# MK20D5 register map
Vendor: Freescale Semiconductor, Inc.; Series: Kinetis_K; File version: 1.6
CPU: CM4 r0p1, little endian, no MPU, no FPU, VTOR, 4 interrupt priority bits
Registers are 32-bit, read-write, reset 0x0 unless marked. A register's access mark holds for its fields unless they carry their own. Offsets are from the block's base; [hi:lo] are bit positions; {n}, {i} and the like mark numbered series.

## USB0 — Universal Serial Bus, OTG Capable Controller
Base 0x40072000; register names take the prefix USB0_
0x00 PERID 8-bit ro reset 0x4 — Peripheral ID Register
  [5:0] ID — Peripheral identification bits
0x04 IDCOMP 8-bit ro reset 0xFB — Peripheral ID Complement Register
  [5:0] NID — Ones complement of peripheral identification bits.
0x08 REV 8-bit ro reset 0x33 — Peripheral Revision Register
  [7:0] REV — Revision
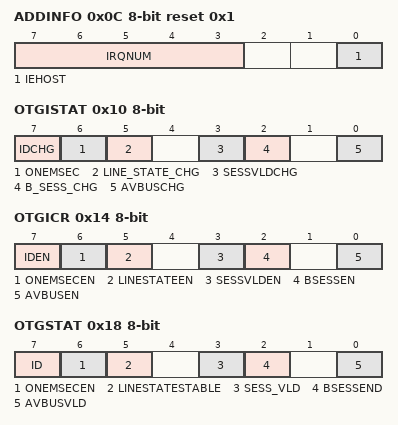
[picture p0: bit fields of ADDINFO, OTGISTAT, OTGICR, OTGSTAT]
0x0C ADDINFO 8-bit ro reset 0x1 — Peripheral Additional Info Register
  [7:3] IRQNUM — Assigned Interrupt Request Number
  [0] IEHOST — This bit is set if host mode is enabled.
0x10 OTGISTAT 8-bit — OTG Interrupt Status Register
  [7] IDCHG — This bit is set when a change in the ID Signal from the USB connector is sensed.
  [6] ONEMSEC — This bit is set when the 1 millisecond timer expires
  [5] LINE_STATE_CHG — This bit is set when the USB line state changes
  [3] SESSVLDCHG — This bit is set when a change in VBUS is detected indicating a session valid or a session no longer valid
  [2] B_SESS_CHG — This bit is set when a change in VBUS is detected on a B device.
  [0] AVBUSCHG — This bit is set when a change in VBUS is detected on an A device.
0x14 OTGICR 8-bit — OTG Interrupt Control Register
  [7] IDEN — ID interrupt enable
    0=The ID interrupt is disabled; 1=The ID interrupt is enabled
  [6] ONEMSECEN — 1 millisecond interrupt enable
    0=The 1msec timer interrupt is disabled; 1=The 1msec timer interrupt is enabled
  [5] LINESTATEEN — Line State change interrupt enable
    0=The LINE_STAT_CHG interrupt is disabled; 1=The LINE_STAT_CHG interrupt is enabled
  [3] SESSVLDEN — Session valid interrupt enable
    0=The SESSVLDCHG interrupt is disabled; 1=The SESSVLDCHG interrupt is enabled
  [2] BSESSEN — B Session END interrupt enable
    0=The B_SESS_CHG interrupt is disabled; 1=The B_SESS_CHG interrupt is enabled
  [0] AVBUSEN — A VBUS Valid interrupt enable
    0=The AVBUSCHG interrupt is disabled; 1=The AVBUSCHG interrupt is enabled
0x18 OTGSTAT 8-bit — OTG Status Register
  [7] ID — Indicates the current state of the ID pin on the USB connector
    0=Indicates a Type A cable has been plugged into the USB connector; 1=Indicates no cable is attached or a Type B cable has been plugged into the USB connector
  [6] ONEMSECEN — This bit is reserved for the 1msec count, but it is not useful to software.
  [5] LINESTATESTABLE — This bit indicates that the internal signals that control the LINE_STATE_CHG bit (bit 5) of the OTGISTAT register have been stable for at least 1 millisecond
    0=The LINE_STAT_CHG bit is not yet stable; 1=The LINE_STAT_CHG bit has been debounced and is stable
  [3] SESS_VLD — Session valid
    0=The VBUS voltage is below the B session Valid threshold; 1=The VBUS voltage is above the B session Valid threshold
  [2] BSESSEND — B Session END
    0=The VBUS voltage is above the B session End threshold; 1=The VBUS voltage is below the B session End threshold
  [0] AVBUSVLD — A VBUS Valid
    0=The VBUS voltage is below the A VBUS Valid threshold; 1=The VBUS voltage is above the A VBUS Valid threshold
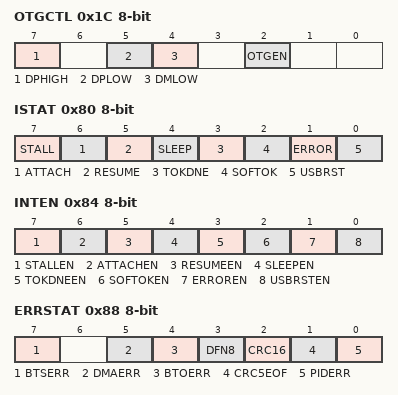
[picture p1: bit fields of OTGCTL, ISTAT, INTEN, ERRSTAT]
0x1C OTGCTL 8-bit — OTG Control Register
  [7] DPHIGH — D+ Data Line pullup resistor enable
    0=D+ pullup resistor is not enabled; 1=D+ pullup resistor is enabled
  [5] DPLOW — D+ Data Line pull-down resistor enable
    0=D+ pulldown resistor is not enabled; 1=D+ pulldown resistor is enabled
  [4] DMLOW — D- Data Line pull-down resistor enable
    0=D- pulldown resistor is not enabled; 1=D- pulldown resistor is enabled
  [2] OTGEN — On-The-Go pullup/pulldown resistor enable
    0=If USB_EN is set and HOST_MODE is clear in the Control Register (CTL), then the D+ Data Line pull-up resistors are enabled. If HOST_MODE is set the D+ and D- Data Line pull-down resistors are engaged.; 1=The pull-up and pull-down controls in this register are used
0x80 ISTAT 8-bit — Interrupt Status Register
  [7] STALL — Stall Interrupt
  [6] ATTACH — Attach Interrupt
  [5] RESUME — This bit is set depending upon the DP/DM signals, and can be used to signal remote wake-up signaling on the USB bus
  [4] SLEEP — This bit is set when the USB Module detects a constant idle on the USB bus for 3 milliseconds
  [3] TOKDNE — This bit is set when the current token being processed has completed
  [2] SOFTOK — This bit is set when the USB Module receives a Start Of Frame (SOF) token
  [1] ERROR — This bit is set when any of the error conditions within the ERRSTAT register occur
  [0] USBRST — This bit is set when the USB Module has decoded a valid USB reset
0x84 INTEN 8-bit — Interrupt Enable Register
  [7] STALLEN — STALL Interrupt Enable
    0=The STALL interrupt is not enabled; 1=The STALL interrupt is enabled
  [6] ATTACHEN — ATTACH Interrupt Enable
    0=The ATTACH interrupt is not enabled; 1=The ATTACH interrupt is enabled
  [5] RESUMEEN — RESUME Interrupt Enable
    0=The RESUME interrupt is not enabled; 1=The RESUME interrupt is enabled
  [4] SLEEPEN — SLEEP Interrupt Enable
    0=The SLEEP interrupt is not enabled; 1=The SLEEP interrupt is enabled
  [3] TOKDNEEN — TOKDNE Interrupt Enable
    0=The TOKDNE interrupt is not enabled; 1=The TOKDNE interrupt is enabled
  [2] SOFTOKEN — SOFTOK Interrupt Enable
    0=The SOFTOK interrupt is not enabled; 1=The SOFTOK interrupt is enabled
  [1] ERROREN — ERROR Interrupt Enable
    0=The ERROR interrupt is not enabled; 1=The ERROR interrupt is enabled
  [0] USBRSTEN — USBRST Interrupt Enable
    0=The USBRST interrupt is not enabled; 1=The USBRST interrupt is enabled
0x88 ERRSTAT 8-bit — Error Interrupt Status Register
  [7] BTSERR — This bit is set when a bit stuff error is detected
  [5] DMAERR — This bit is set if the USB Module has requested a DMA access to read a new BDT but has not been given the bus before it needs to receive or transmit data
  [4] BTOERR — This bit is set when a bus turnaround timeout error occurs
  [3] DFN8 — This bit is set if the data field received was not 8 bits in length
  [2] CRC16 — This bit is set when a data packet is rejected due to a CRC16 error.
  [1] CRC5EOF — This error interrupt has two functions
  [0] PIDERR — This bit is set when the PID check field fails.
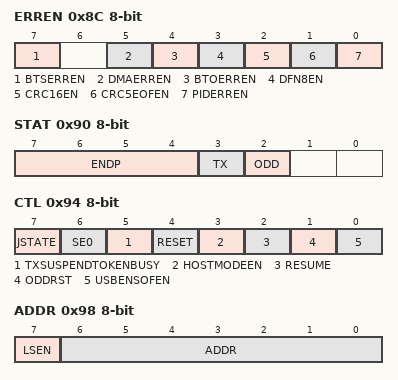
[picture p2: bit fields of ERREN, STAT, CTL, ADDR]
0x8C ERREN 8-bit — Error Interrupt Enable Register
  [7] BTSERREN — BTSERR Interrupt Enable
    0=The BTSERR interrupt is not enabled; 1=The BTSERR interrupt is enabled
  [5] DMAERREN — DMAERR Interrupt Enable
    0=The DMAERR interrupt is not enabled; 1=The DMAERR interrupt is enabled
  [4] BTOERREN — BTOERR Interrupt Enable
    0=The BTOERR interrupt is not enabled; 1=The BTOERR interrupt is enabled
  [3] DFN8EN — DFN8 Interrupt Enable
    0=The DFN8 interrupt is not enabled; 1=The DFN8 interrupt is enabled
  [2] CRC16EN — CRC16 Interrupt Enable
    0=The CRC16 interrupt is not enabled; 1=The CRC16 interrupt is enabled
  [1] CRC5EOFEN — CRC5/EOF Interrupt Enable
    0=The CRC5/EOF interrupt is not enabled; 1=The CRC5/EOF interrupt is enabled
  [0] PIDERREN — PIDERR Interrupt Enable
    0=The PIDERR interrupt is not enabled; 1=The PIDERR interrupt is enabled
0x90 STAT 8-bit ro — Status Register
  [7:4] ENDP — This four-bit field encodes the endpoint address that received or transmitted the previous token
  [3] TX — Transmit Indicator
    0=The most recent transaction was a Receive operation; 1=The most recent transaction was a Transmit operation
  [2] ODD — this bit is set if the last Buffer Descriptor updated was in the odd bank of the BDT.
0x94 CTL 8-bit — Control Register
  [7] JSTATE — Live USB differential receiver JSTATE signal
  [6] SE0 — Live USB Single Ended Zero signal
  [5] TXSUSPENDTOKENBUSY — When the USB Module is in Host mode TOKEN_BUSY is set when the USB Module is busy executing a USB token and no more token commands should be written to the Token Register
  [4] RESET — Setting this bit enables the USB Module to generate USB reset signaling
  [3] HOSTMODEEN — When set to 1, this bit enables the USB Module to operate in Host mode
  [2] RESUME — When set to 1 this bit enables the USB Module to execute resume signaling
  [1] ODDRST — Setting this bit to 1 resets all the BDT ODD ping/pong bits to 0, which then specifies the EVEN BDT bank
  [0] USBENSOFEN — USB Enable
    0=The USB Module is disabled; 1=The USB Module is enabled
0x98 ADDR 8-bit — Address Register
  [7] LSEN — Low Speed Enable bit
  [6:0] ADDR — USB address
0x9C BDTPAGE1 8-bit — BDT Page Register 1
  [7:1] BDTBA — This field provides address bits 15 through 9 of the BDT base address.
0xA0 FRMNUML 8-bit — Frame Number Register Low
  [7:0] FRM — This 8-bit field and the 3-bit field in the Frame Number Register High are used to compute the address where the current Buffer Descriptor Table (BDT) resides in system memory
0xA4 FRMNUMH 8-bit — Frame Number Register High
  [2:0] FRM — This 3-bit field and the 8-bit field in the Frame Number Register Low are used to compute the address where the current Buffer Descriptor Table (BDT) resides in system memory
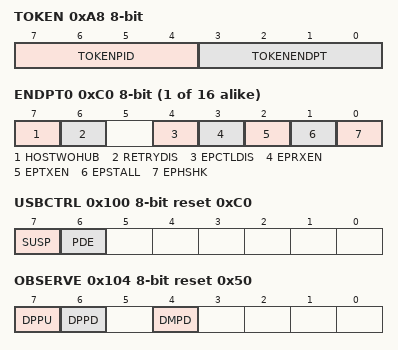
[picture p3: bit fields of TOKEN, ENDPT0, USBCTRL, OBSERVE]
0xA8 TOKEN 8-bit
  [7:4] TOKENPID — This 4-bit field contains the token type executed by the USB Module.
    1=OUT Token. USB Module performs an OUT (TX) transaction.; 9=IN Token. USB Module performs an In (RX) transaction.; 13=SETUP Token. USB Module performs a SETUP (TX) transaction
  [3:0] TOKENENDPT — This 4 bit field holds the Endpoint address for the token command
0xAC SOFTHLD 8-bit — SOF Threshold Register
  [7:0] CNT — This 8-bit field represents the SOF count threshold in byte times.
0xB0 BDTPAGE2 8-bit — BDT Page Register 2
  [7:0] BDTBA — This 8 bit field provides address bits 23 through 16 of the BDT base address, which defines where the Buffer Descriptor Table resides in system memory
0xB4 BDTPAGE3 8-bit — BDT Page Register 3
  [7:0] BDTBA — This 8 bit field provides address bits 31 through 24 of the BDT base address, which defines where the Buffer Descriptor Table resides in system memory
{0xC0+4i} ENDPT{i} (i=0..15) 8-bit — Endpoint Control Register
  [7] HOSTWOHUB, [6] RETRYDIS, [4] EPCTLDIS, [3] EPRXEN, [2] EPTXEN, [1] EPSTALL, [0] EPHSHK
0x100 USBCTRL 8-bit reset 0xC0 — USB Control Register
  [7] SUSP — Places the USB transceiver into the suspend state.
    0=USB transceiver is not in suspend state; 1=USB transceiver is in suspend state
  [6] PDE — Enables the weak pulldowns on the USB transceiver.
    0=Weak pulldowns are disabled on D+ and D-; 1=Weak pulldowns are enabled on D+ and D-
0x104 OBSERVE 8-bit ro reset 0x50 — USB OTG Observe Register
  [7] DPPU — Provides observability of the D+ Pull Up enable at the USB transceiver.
    0=D+ pullup disabled; 1=D+ pullup enabled
  [6] DPPD — Provides observability of the D+ Pull Down enable at the USB transceiver.
    0=D+ pulldown disabled; 1=D+ pulldown enabled
  [4] DMPD — Provides observability of the D- Pull Down enable at the USB transceiver.
    0=D- pulldown disabled; 1=D- pulldown enabled
0x108 CONTROL 8-bit — USB OTG Control Register
  [4] DPPULLUPNONOTG — Provides control of the DP PULLUP in the USB OTG module, if USB is configured in non-OTG device mode
    0=DP Pull up in non-OTG device mode is not enabled; 1=DP Pull up in non-OTG device mode is enabled
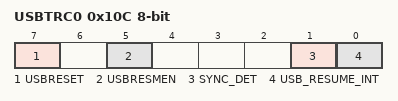
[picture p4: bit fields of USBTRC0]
0x10C USBTRC0 8-bit — USB Transceiver Control Register 0
  [7] USBRESET wo
    0=Normal USB module operation; 1=Returns the USB module to its reset state
  [5] USBRESMEN — Asynchronous Resume Interrupt Enable
    0=USB asynchronous wakeup from suspend mode disabled; 1=USB asynchronous wakeup from suspend mode enabled. The asynchronous resume interrupt differs from the synchronous resume interrupt in that it asynchronously detects K-state using the unfiltered state of the D+ and D- pins. This interupt should only be enabled when the Transceiver is suspended.
  [1] SYNC_DET ro — Synchronous USB Interrupt Detect
    0=Synchronous interrupt has not been detected; 1=Synchronous interrupt has been detected
  [0] USB_RESUME_INT ro — USB Asynchronous Interrupt
    0=No interrupt was generated; 1=Interrupt was generated because of the USB asynchronous interrupt
0x114 USBFRMADJUST 8-bit — Frame Adjust Register
  [7:0] ADJ — Frame Adjustment
